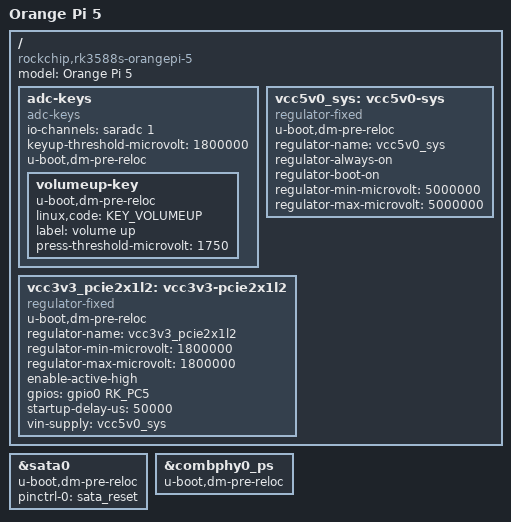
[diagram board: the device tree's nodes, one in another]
// SPDX-License-Identifier: (GPL-2.0+ OR MIT)
/*
 * Copyright (c) 2021 Rockchip Electronics Co., Ltd
 *
 */

/dts-v1/;
#include "rk3588.dtsi"
#include "rk3588-u-boot.dtsi"
#include <dt-bindings/input/input.h>

/ {
	model = "Orange Pi 5";
	compatible = "rockchip,rk3588s-orangepi-5", "rockchip,rk3588";

	adc-keys {
		compatible = "adc-keys";
		io-channels = <&saradc 1>;
		io-channel-names = "buttons";
		keyup-threshold-microvolt = <1800000>;
		u-boot,dm-pre-reloc;
		status = "okay";

		volumeup-key {
			u-boot,dm-pre-reloc;
			linux,code = <KEY_VOLUMEUP>;
			label = "volume up";
			press-threshold-microvolt = <1750>;
		};
	};

	vcc5v0_sys: vcc5v0-sys {
		u-boot,dm-pre-reloc;
		compatible = "regulator-fixed";
		regulator-name = "vcc5v0_sys";
		regulator-always-on;
		regulator-boot-on;
		regulator-min-microvolt = <5000000>;
		regulator-max-microvolt = <5000000>;
	};

	vcc3v3_pcie2x1l2: vcc3v3-pcie2x1l2 {
		u-boot,dm-pre-reloc;
		compatible = "regulator-fixed";
		regulator-name = "vcc3v3_pcie2x1l2";
		regulator-min-microvolt = <1800000>;
		regulator-max-microvolt = <1800000>;
		enable-active-high;
		//regulator-boot-on;
		//regulator-always-on;
		gpios = <&gpio0 RK_PC5 GPIO_ACTIVE_HIGH>;
		startup-delay-us = <50000>;
		vin-supply = <&vcc5v0_sys>;
	};
};

#if 1
&sata0 {
	u-boot,dm-pre-reloc;
	pinctrl-names = "default";
	pinctrl-0 = <&sata_reset>;
	status = "okay";
};

# else

&pcie2x1l2 {
	u-boot,dm-pre-reloc;
	reset-gpios = <&gpio3 RK_PD1 GPIO_ACTIVE_HIGH>;
	vpcie3v3-supply = <&vcc3v3_pcie2x1l2>;
	status = "okay";
};
#endif

&combphy0_ps {
	u-boot,dm-pre-reloc;
	status = "okay";
};
